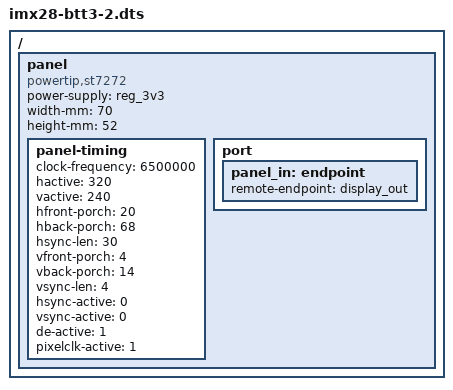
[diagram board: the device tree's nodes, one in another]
// SPDX-License-Identifier: GPL-2.0-or-later OR MIT
/*
 * Copyright 2024
 * Lukasz Majewski, DENX Software Engineering, lukma@denx.de
 */

/dts-v1/;
#include "imx28-btt3.dtsi"

/ {
	panel {
		compatible = "powertip,st7272", "panel-dpi";
		power-supply = <&reg_3v3>;
		width-mm = <70>;
		height-mm = <52>;

		panel-timing {
			clock-frequency = <6500000>;
			hactive = <320>;
			vactive = <240>;
			hfront-porch = <20>;
			hback-porch = <68>;
			hsync-len = <30>;
			vfront-porch = <4>;
			vback-porch = <14>;
			vsync-len = <4>;
			hsync-active = <0>;
			vsync-active = <0>;
			de-active = <1>;
			pixelclk-active = <1>;
		};

		port {
			panel_in: endpoint {
				remote-endpoint = <&display_out>;
			};
		};
	};
};
